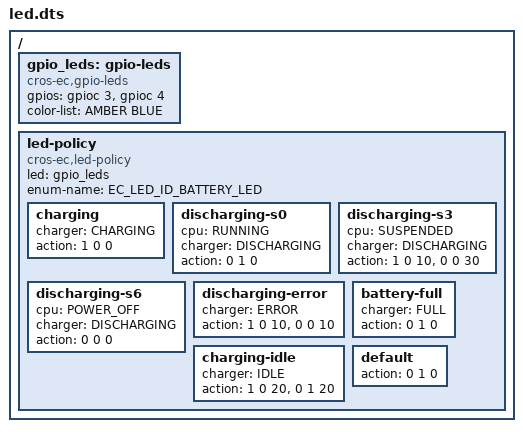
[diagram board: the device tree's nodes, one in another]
/* Copyright 2022 The Chromium OS Authors. All rights reserved.
 * Use of this source code is governed by a BSD-style license that can be
 * found in the LICENSE file.
 */

#include <dt-bindings/colors.h>

/ {
	gpio_leds: gpio-leds {
		compatible = "cros-ec,gpio-leds";

		gpios = <&gpioc 3 0>,
			<&gpioc 4 0>;
		color-list = <AMBER BLUE>;
	};

	led-policy {
		compatible = "cros-ec,led-policy";

		led = <&gpio_leds>;
		enum-name = "EC_LED_ID_BATTERY_LED";

		/*
		 * First value is amber LED,
		 * second blue LED,
		 * third duration in tenths of a second.
		 */
		charging {
			charger = "CHARGING";
			action = <1 0 0>;
		};
		discharging-s0 {
			cpu = "RUNNING";
			charger = "DISCHARGING";
			action = <0 1 0>;
		};
		discharging-s3 {
			cpu = "SUSPENDED";
			charger = "DISCHARGING";
			action = <1 0 10>, <0 0 30>;
		};
		discharging-s6 {
			cpu = "POWER_OFF";
			charger = "DISCHARGING";
			action = <0 0 0>;
		};
		discharging-error {
			charger = "ERROR";
			action = <1 0 10>, <0 0 10>;
		};
		battery-full {
			charger = "FULL";
			action = <0 1 0>;
		};
		charging-idle {
			charger = "IDLE";
			action = <1 0 20>, <0 1 20>;
		};
		default {
			action = <0 1 0>;
		};
	};
};
